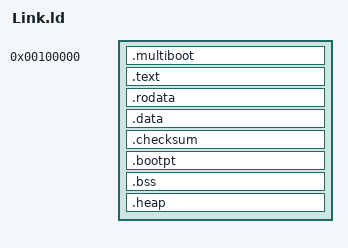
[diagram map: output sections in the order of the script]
OUTPUT_FORMAT(elf64-x86-64)
ENTRY(Start)

PHDRS
{
  text    PT_LOAD FLAGS(5);   /* PF_R | PF_X  (читаем и исполняем) */
  rodata  PT_LOAD FLAGS(4);   /* PF_R         (только читаем)     */
  data    PT_LOAD FLAGS(6);   /* PF_R | PF_W  (читаем и пишем)    */
  checksum PT_LOAD FLAGS(4);  /* PF_R         (только читаем)     */
}

SECTIONS
{
    /* ============================================================
     * Физический адрес (нижняя половина)
     * ============================================================ */
    . = 0x00100000;
    KernelPhysStart = .;
    
    /* Адрес в higher half, куда скопируем ядро */
    KernelVirtStart = 0xFFFFFFFF80000000 + KernelPhysStart;
    
    /* ============================================================
     * MULTIBOOT
     * ============================================================ */
    .multiboot ALIGN(8) : {
        KEEP(*(.multiboot))
        KEEP(*(.multiboot.*))
    } :text
    
    /* ============================================================
     * .TEXT — код (R-X)
     * ============================================================ */
    KernelTextStart = .;
    .text : {
        *(.text)
        *(.text*)
        *(.apboot)
    } :text
    KernelTextEnd = .;
    
    /* ============================================================
     * .RODATA — константы (R--)
     * ============================================================ */
    KernelRodataStart = .;
    .rodata : {
        *(.rodata)
        *(.rodata*)
    } :rodata
    KernelRodataEnd = .;
    
    /* ============================================================
     * .DATA — глобальные переменные (RW-)
     * ============================================================ */
    KernelDataStart = .;
    .data : {
        *(.data)
        *(.data*)
    } :data
    KernelDataEnd = .;
    
    /* ============================================================
     * .CHECKSUM — хеш ядра (встраивается скриптом)
     * ============================================================ */
    .checksum : {
        __checksum_start = .;
        KEEP(*(.checksum))
        __checksum_end = .;
    } :checksum

    /* ============================================================
     * .BOOTPT — таблицы страниц (NOLOAD, не загружается)
     * ============================================================ */
    .bootpt (NOLOAD) : ALIGN(4096) {
        BootPtPhysStart = .;
        *(.bootpt)
        BootPtPhysEnd = .;
    }

    /* ============================================================
     * .BSS — неинициализированные данные (RW-)
     * ============================================================ */
    KernelBssStart = .;
    .bss : {
        *(.bss)
        *(.bss*)
        *(COMMON)
        
        . = ALIGN(16);
        StackStart = .;
        . += 262144;
        StackEnd = .;

        . = ALIGN(16);
        TssBuffer = .;
        . += 104;
    } :data
    KernelBssEnd = .;

    /* ============================================================
     * .HEAP — куча (NOLOAD, динамическая)
     * ============================================================ */
    .heap (NOLOAD) : {
        . = ALIGN(8);
        HeapStart = .;
        . = . + 16 * 1024 * 1024;
        HeapEnd = .;
    } :data

    /* ============================================================
     * DISCARD — выкидываем мусор
     * ============================================================ */
    /DISCARD/ : {
        *(.comment)
        *(.note*)
        *(.eh_frame)
        *(.eh_frame_hdr)
        *(.debug*)
        *(.got)
        *(.got.plt)
        *(.plt)
        *(.note.GNU-stack)
    }
    
    KernelPhysEnd = .;
    
    /* Символы для копирования */
    KernelSize = KernelPhysEnd - KernelPhysStart;
}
